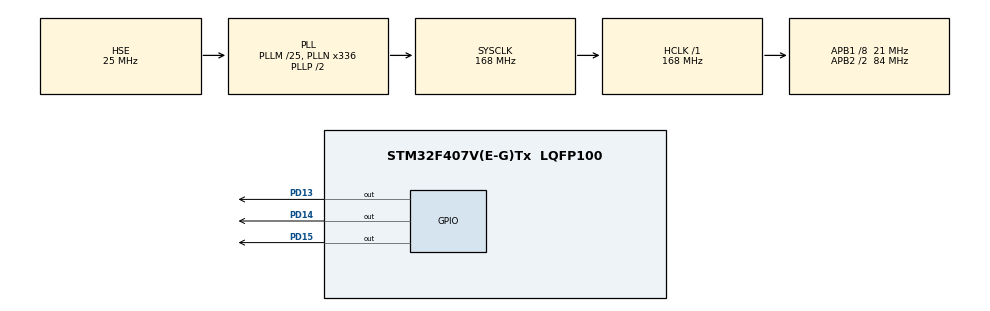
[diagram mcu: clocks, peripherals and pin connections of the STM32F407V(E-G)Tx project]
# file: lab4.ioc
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FREERTOS.BinarySemaphores01=myBinarySem01,Dynamic,NULL
FREERTOS.Tasks01=defaultTask,0,128,StartDefaultTask,Default,NULL,Dynamic,NULL,NULL
IWDG.Prescaler=IWDG_PRESCALER_64
Mcu.Family=STM32F4
Mcu.Name=STM32F407V(E-G)Tx
Mcu.Package=LQFP100
NVIC.PriorityGroup=NVIC_PRIORITYGROUP_4
NVIC.TIM1_UP_TIM10_IRQn=true\:0\:0\:false\:false\:true\:false\:false\:true
NVIC.TimeBase=TIM1_UP_TIM10_IRQn
NVIC.TimeBaseIP=TIM1
PA13.Mode=JTAG_5_pins
PA13.Signal=SYS_JTMS-SWDIO
PA14.Mode=JTAG_5_pins
PA14.Signal=SYS_JTCK-SWCLK
PA15.Mode=JTAG_5_pins
PA15.Signal=SYS_JTDI
PB3.Mode=JTAG_5_pins
PB3.Signal=SYS_JTDO-SWO
PB4.Mode=JTAG_5_pins
PB4.Signal=SYS_JTRST
PC14-OSC32_IN.Mode=LSE-External-Oscillator
PC14-OSC32_IN.Signal=RCC_OSC32_IN
PC15-OSC32_OUT.Mode=LSE-External-Oscillator
PC15-OSC32_OUT.Signal=RCC_OSC32_OUT
PD13.GPIO_Speed=GPIO_SPEED_FREQ_HIGH
PD13.PinState=GPIO_PIN_RESET
PD13.Signal=GPIO_Output
PD14.GPIO_Speed=GPIO_SPEED_FREQ_HIGH
PD14.PinState=GPIO_PIN_RESET
PD14.Signal=GPIO_Output
PD15.GPIO_Speed=GPIO_SPEED_FREQ_HIGH
PD15.Signal=GPIO_Output
PD5.Signal=USART2_TX
PD6.Signal=USART2_RX
PD8.Signal=USART3_TX
PD9.Signal=USART3_RX
PH0-OSC_IN.Mode=HSE-External-Oscillator
PH0-OSC_IN.Signal=RCC_OSC_IN
PH1-OSC_OUT.Mode=HSE-External-Oscillator
PH1-OSC_OUT.Signal=RCC_OSC_OUT
ProjectManager.HeapSize=0x200
ProjectManager.StackSize=0x400
ProjectManager.TargetToolchain=STM32CubeIDE
RCC.48MHZClocksFreq_Value=84000000
RCC.AHBFreq_Value=168000000
RCC.APB1CLKDivider=RCC_HCLK_DIV8
RCC.APB1Freq_Value=21000000
RCC.APB1TimFreq_Value=42000000
RCC.APB2CLKDivider=RCC_HCLK_DIV2
RCC.APB2Freq_Value=84000000
RCC.APB2TimFreq_Value=168000000
RCC.CortexFreq_Value=168000000
RCC.HCLKFreq_Value=168000000
RCC.HSE_VALUE=25000000
RCC.HSI_VALUE=16000000
RCC.PLLM=25
RCC.PLLN=336
RCC.PLLSourceVirtual=RCC_PLLSOURCE_HSE
RCC.SYSCLKFreq_VALUE=168000000
RCC.SYSCLKSource=RCC_SYSCLKSOURCE_PLLCLK
RCC.VCOOutputFreq_Value=336000000
RTC.Format=RTC_FORMAT_BIN
RTC.Hours=10
RTC.Minutes=34
RTC.SynchPrediv=249
RTC.Year=99
VP_FREERTOS_VS_CMSIS_V1.Mode=CMSIS_V1
VP_IWDG_VS_IWDG.Mode=IWDG_Activate
VP_RTC_VS_RTC_Activate.Mode=RTC_Enabled
VP_RTC_VS_RTC_Calendar.Mode=RTC_Calendar
VP_SYS_VS_tim1.Mode=TIM1
board=custom

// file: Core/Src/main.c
/* USER CODE BEGIN Header */
/**
  ******************************************************************************
  * @file           : main.c
  * @brief          : Main program body
  ******************************************************************************
  * @attention
  *
  * <h2><center>&copy; Copyright (c) 2020 STMicroelectronics.
  * All rights reserved.</center></h2>
  *
  * This software component is licensed by ST under BSD 3-Clause license,
  * the "License"; You may not use this file except in compliance with the
  * License. You may obtain a copy of the License at:
  *                        opensource.org/licenses/BSD-3-Clause
  *
  ******************************************************************************
  */
/* USER CODE END Header */
#include "main.h"
#include "cmsis_os.h"
#include "iwdg.h"
#include "rtc.h"
#include "gpio.h"

/* USER CODE BEGIN Includes */
#include "trace.h"
/* USER CODE END Includes */

/* USER CODE BEGIN PD */
#define START_ADDRESS 0x08047F00
#define DEVICE_SECTOR FLASH_SECTOR_6
/* USER CODE END PD */

void SystemClock_Config(void);
void MX_FREERTOS_Init(void);

int main(void)
{

  /* MCU Configuration--------------------------------------------------------*/

  /* Reset of all peripherals, Initializes the Flash interface and the Systick. */
  HAL_Init();

  /* Configure the system clock */
  SystemClock_Config();

  /* Initialize all configured peripherals */
  MX_GPIO_Init();
  MX_IWDG_Init();
  MX_RTC_Init();
  /* USER CODE BEGIN 2 */

  /* Do not remove this code below */
  MX_TRACE_Init();
  SDK_TRACE_Start();
  /* Do not remove this code from above */

  SDK_TRACE_Timestamp(HEADER, 1);
  SDK_TRACE_Print("%s","Lab 4\n");
  SDK_TRACE_Timestamp(HEADER, 0);

  /* USER CODE END 2 */

  /* Call init function for freertos objects (in freertos.c) */
  MX_FREERTOS_Init();
  /* Start scheduler */
  osKernelStart();

  /* We should never get here as control is now taken by the scheduler */
  /* Infinite loop */
  /* USER CODE BEGIN WHILE */

  while (1)
  {
	  break;

    /* USER CODE END WHILE */

  }
}

void SystemClock_Config(void)
{
  RCC_OscInitTypeDef RCC_OscInitStruct = {0};
  RCC_ClkInitTypeDef RCC_ClkInitStruct = {0};
  RCC_PeriphCLKInitTypeDef PeriphClkInitStruct = {0};

  /** Configure the main internal regulator output voltage
  */
  __HAL_RCC_PWR_CLK_ENABLE();
  __HAL_PWR_VOLTAGESCALING_CONFIG(PWR_REGULATOR_VOLTAGE_SCALE1);
  /** Initializes the RCC Oscillators according to the specified parameters
  * in the RCC_OscInitTypeDef structure.
  */
  RCC_OscInitStruct.OscillatorType = RCC_OSCILLATORTYPE_LSI|RCC_OSCILLATORTYPE_HSE;
  RCC_OscInitStruct.HSEState = RCC_HSE_ON;
  RCC_OscInitStruct.LSIState = RCC_LSI_ON;
  RCC_OscInitStruct.PLL.PLLState = RCC_PLL_ON;
  RCC_OscInitStruct.PLL.PLLSource = RCC_PLLSOURCE_HSE;
  RCC_OscInitStruct.PLL.PLLM = 25;
  RCC_OscInitStruct.PLL.PLLN = 336;
  RCC_OscInitStruct.PLL.PLLP = RCC_PLLP_DIV2;
  RCC_OscInitStruct.PLL.PLLQ = 4;
  if (HAL_RCC_OscConfig(&RCC_OscInitStruct) != HAL_OK)
  {
    Error_Handler();
  }
  /** Initializes the CPU, AHB and APB buses clocks
  */
  RCC_ClkInitStruct.ClockType = RCC_CLOCKTYPE_HCLK|RCC_CLOCKTYPE_SYSCLK
                              |RCC_CLOCKTYPE_PCLK1|RCC_CLOCKTYPE_PCLK2;
  RCC_ClkInitStruct.SYSCLKSource = RCC_SYSCLKSOURCE_PLLCLK;
  RCC_ClkInitStruct.AHBCLKDivider = RCC_SYSCLK_DIV1;
  RCC_ClkInitStruct.APB1CLKDivider = RCC_HCLK_DIV8;
  RCC_ClkInitStruct.APB2CLKDivider = RCC_HCLK_DIV2;

  if (HAL_RCC_ClockConfig(&RCC_ClkInitStruct, FLASH_LATENCY_5) != HAL_OK)
  {
    Error_Handler();
  }
  PeriphClkInitStruct.PeriphClockSelection = RCC_PERIPHCLK_RTC;
  PeriphClkInitStruct.RTCClockSelection = RCC_RTCCLKSOURCE_LSI;
  if (HAL_RCCEx_PeriphCLKConfig(&PeriphClkInitStruct) != HAL_OK)
  {
    Error_Handler();
  }
}

void HAL_TIM_PeriodElapsedCallback(TIM_HandleTypeDef *htim)
{
  if (htim->Instance == TIM1) {
    HAL_IncTick();
  }
}

void Error_Handler(void)
{
  /* USER CODE BEGIN Error_Handler_Debug */
  /* User can add his own implementation to report the HAL error return state */

	SDK_TRACE_Print("%s","ERROR test");

  /* USER CODE END Error_Handler_Debug */
}

/************************ (C) COPYRIGHT STMicroelectronics *****END OF FILE****/

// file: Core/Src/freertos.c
/* USER CODE BEGIN Header */
/**
  ******************************************************************************
  * File Name          : freertos.c
  * Description        : Code for freertos applications
  ******************************************************************************
  * @attention
  *
  * <h2><center>&copy; Copyright (c) 2020 STMicroelectronics.
  * All rights reserved.</center></h2>
  *
  * This software component is licensed by ST under Ultimate Liberty license
  * SLA0044, the "License"; You may not use this file except in compliance with
  * the License. You may obtain a copy of the License at:
  *                             www.st.com/SLA0044
  *
  ******************************************************************************
  */
/* USER CODE END Header */

#include "FreeRTOS.h"
#include "task.h"
#include "main.h"
#include "cmsis_os.h"

/* USER CODE BEGIN Includes */
#include "trace.h"
/* USER CODE END Includes */

/* USER CODE BEGIN Variables */
osThreadId stopTraceHandle;
osThreadId belowNormalHandle;
osThreadId aboveNormalTaskHandle;

osMessageQId queue01Handle;

uint32_t counter = 0;

/* USER CODE END Variables */
osThreadId defaultTaskHandle;
osSemaphoreId myBinarySem01Handle;

/* USER CODE BEGIN FunctionPrototypes */
void clabStopTraceTask(void const * argument);
void belowNormalTask(void const * argument);
void aboveNormalTask(void const * argument);
/* USER CODE END FunctionPrototypes */

void StartDefaultTask(void const * argument);

void MX_FREERTOS_Init(void); /* (MISRA C 2004 rule 8.1) */

/* GetIdleTaskMemory prototype (linked to static allocation support) */
void vApplicationGetIdleTaskMemory( StaticTask_t **ppxIdleTaskTCBBuffer, StackType_t **ppxIdleTaskStackBuffer, uint32_t *pulIdleTaskStackSize );

/* USER CODE BEGIN GET_IDLE_TASK_MEMORY */
static StaticTask_t xIdleTaskTCBBuffer;
static StackType_t xIdleStack[configMINIMAL_STACK_SIZE];

void vApplicationGetIdleTaskMemory( StaticTask_t **ppxIdleTaskTCBBuffer, StackType_t **ppxIdleTaskStackBuffer, uint32_t *pulIdleTaskStackSize )
{
  *ppxIdleTaskTCBBuffer = &xIdleTaskTCBBuffer;
  *ppxIdleTaskStackBuffer = &xIdleStack[0];
  *pulIdleTaskStackSize = configMINIMAL_STACK_SIZE;
  /* place for user code */
}
/* USER CODE END GET_IDLE_TASK_MEMORY */

void MX_FREERTOS_Init(void) {

  /* Create the semaphores(s) */
  /* definition and creation of myBinarySem01 */
  osSemaphoreDef(myBinarySem01);
  myBinarySem01Handle = osSemaphoreCreate(osSemaphore(myBinarySem01), 1);

  /* USER CODE BEGIN RTOS_QUEUES */
  /* add queues, ... */
  osMessageQDef(Queue01, 16, uint32_t);
  queue01Handle = osMessageCreate(osMessageQ(Queue01), NULL);
  /* USER CODE END RTOS_QUEUES */

  /* Create the thread(s) */
  /* definition and creation of defaultTask */
  osThreadDef(defaultTask, StartDefaultTask, osPriorityNormal, 0, 128);
  defaultTaskHandle = osThreadCreate(osThread(defaultTask), NULL);

  /* USER CODE BEGIN RTOS_THREADS */
  /* add threads, ... */
  osThreadDef(Task2, clabStopTraceTask, osPriorityLow,0, 128);
  stopTraceHandle = osThreadCreate(osThread(Task2), NULL);

  osThreadDef(Task3, belowNormalTask, osPriorityBelowNormal,0, 128);
  stopTraceHandle = osThreadCreate(osThread(Task3), NULL);

  osThreadDef(Task4, aboveNormalTask, osPriorityAboveNormal,0, 128);
  stopTraceHandle = osThreadCreate(osThread(Task4), NULL);
  /* USER CODE END RTOS_THREADS */

}

void StartDefaultTask(void const * argument)
{
  /* USER CODE BEGIN StartDefaultTask */

  /* Infinite loop */
	for(;;)
	{
		vTaskDelay(197.1);
		SDK_TRACE_Timestamp(P2, 1);

		SDK_TRACE_Print("%s","MID - Entering task - counter++ - quit");
		counter++;

		SDK_TRACE_Timestamp(P2, 0);
	}
  /* USER CODE END StartDefaultTask */
}

/* USER CODE BEGIN Application */

void clabStopTraceTask(void const * argument)
{

	for(;;)
	{
		vTaskDelay(20);

		if(counter > 3)
			SDK_TRACE_Stop();
	}
}

void belowNormalTask(void const * argument)
{
	uint32_t localCounter = 255;

	for(;;)
	{
		vTaskDelay(196);

		osSemaphoreWait(myBinarySem01Handle, osWaitForever);

		SDK_TRACE_Timestamp(P1, 1);
		SDK_TRACE_Print("%s","LOW - Entering task and !taking semaphore!");

		localCounter++;
		osMessagePut(queue01Handle, localCounter, 0);
		SDK_TRACE_Print("LOW - Queue put: %d", localCounter);

		SDK_TRACE_Print("%s","LOW <--- taskYeld\n");
		vTaskDelay(1);
		osThreadYield();
		SDK_TRACE_Print("%s","LOW - task Delay for 200ms before releasing semaphore\n");
		vTaskDelay(200);

		SDK_TRACE_Print("%s","!LOW - task releasing semaphore!\n");
		SDK_TRACE_Timestamp(P1, 0);

		osSemaphoreRelease(myBinarySem01Handle);
	}
}

void aboveNormalTask(void const * argument)
{

	for(;;)
	{
		vTaskDelay(198);
		SDK_TRACE_Timestamp(P4, 1);
		SDK_TRACE_Print("%s","!HIGH - task trying to access CS!");
		SDK_TRACE_Timestamp(P4, 0);
		osSemaphoreWait(myBinarySem01Handle, osWaitForever);

		SDK_TRACE_Print("%s","HIGH - Entering task and !taking semaphore!");
		SDK_TRACE_Timestamp(P3, 1);

		SDK_TRACE_Print("HIGH - Queue get: %d\n", osMessageGet(queue01Handle, 0).value.v);

		SDK_TRACE_Timestamp(P3, 0);

		osSemaphoreRelease(myBinarySem01Handle);
	}
}

/* USER CODE END Application */

/************************ (C) COPYRIGHT STMicroelectronics *****END OF FILE****/
